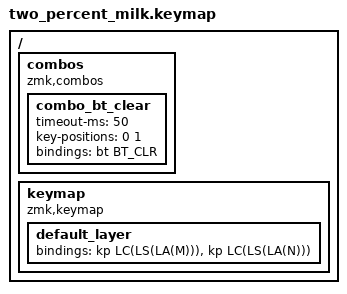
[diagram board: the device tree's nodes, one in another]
/*
 * Copyright (c) 2022 The ZMK Contributors
 *
 * SPDX-License-Identifier: MIT
 */

#include <behaviors.dtsi>
#include <dt-bindings/zmk/keys.h>
#include <dt-bindings/zmk/bt.h>

/ {
    combos {
        compatible = "zmk,combos";
        combo_bt_clear {
            timeout-ms = <50>;
            key-positions = <0 1>;
            bindings = <&bt BT_CLR>;
        };
    };

    keymap {
        compatible = "zmk,keymap";
    
        default_layer {
            bindings = <
                &kp LC(LS(LA(M)))
                &kp LC(LS(LA(N)))
            >;
        };
    };
};
